# STM32H7B3xxQ register map
File version: 1.0
Registers are 32-bit, read-write, reset 0x0 unless marked. A register's access mark holds for its fields unless they carry their own. Offsets are from the block's base; [hi:lo] are bit positions; {n}, {i} and the like mark numbered series.

## TAMP — Tamper and backup registers
Base 0x58004400
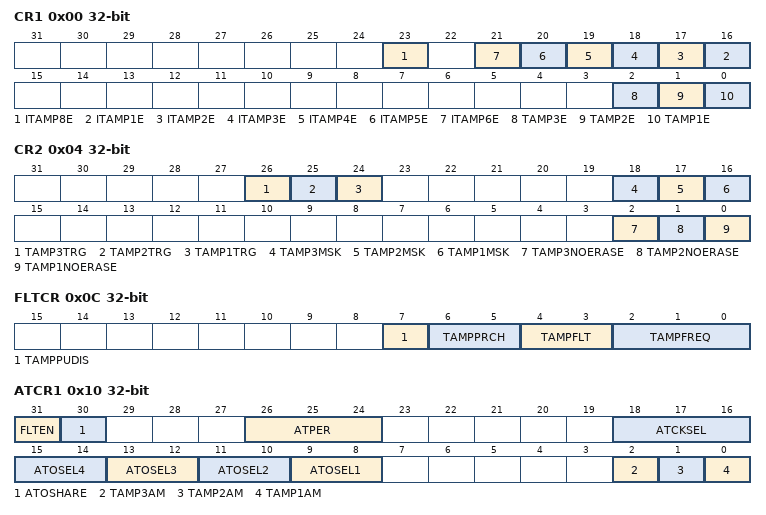
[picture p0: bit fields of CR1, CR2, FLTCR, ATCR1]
0x00 CR1 — TAMP configuration register 1
  [23] ITAMP8E, [n+15] ITAMP{n}E (n=1..6), [2] TAMP3E, [1] TAMP2E, [0] TAMP1E
0x04 CR2 — TAMP configuration register 2
  [26] TAMP3TRG, [25] TAMP2TRG, [24] TAMP1TRG, [18] TAMP3MSK, [17] TAMP2MSK, [16] TAMP1MSK, [2] TAMP3NOERASE, [1] TAMP2NOERASE, [0] TAMP1NOERASE
0x0C FLTCR — TAMP filter control register
  [7] TAMPPUDIS
  [6:5] TAMPPRCH
    0=DURATION_1RTCCLK (Tamper pins are pre-charged before sampling during 1 RTCCLK cycle); 1=DURATION_2RTCCLK (Tamper pins are pre-charged before sampling during 2 RTCCLK cycles); 2=DURATION_4RTCCLK (Tamper pins are pre-charged before sampling during 4 RTCCLK cycles); 3=DURATION_8RTCCLK (Tamper pins are pre-charged before sampling during 8 RTCCLK cycles)
  [4:3] TAMPFLT
    0=DISABLE (Tamper filter is disabled); 1=FILTER_2SAMPLE (Tamper is activated after 2 consecutive samples at the active level); 2=FILTER_4SAMPLE (Tamper is activated after 4 consecutive samples at the active level); 3=FILTER_8SAMPLE (Tamper is activated after 8 consecutive samples at the active level.)
  [2:0] TAMPFREQ
    0=SAMPLFREQDIV_32768 (Each of the tamper inputs are sampled with a frequency = RTCCLK / 32768); 1=SAMPLFREQDIV_16384 (Each of the tamper inputs are sampled with a frequency = RTCCLK / 16384); 2=SAMPLFREQDIV_8192 (Each of the tamper inputs are sampled with a frequency = RTCCLK / 8192); 3=SAMPLFREQDIV_4096 (Each of the tamper inputs are sampled with a frequency = RTCCLK / 4096); 4=SAMPLFREQDIV_2048 (Each of the tamper inputs are sampled with a frequency = RTCCLK / 2048); 5=SAMPLFREQDIV_1024 (Each of the tamper inputs are sampled with a frequency = RTCCLK / 1024); 6=SAMPLFREQDIV_512 (Each of the tamper inputs are sampled with a frequency = RTCCLK / 512); 7=SAMPLFREQDIV_256 (Each of the tamper inputs are sampled with a frequency = RTCCLK / 256)
0x10 ATCR1 — TAMP active tamper control register
  [31] FLTEN, [30] ATOSHARE, [26:24] ATPER, [18:16] ATCKSEL, [2n+7:2n+6] ATOSEL{n} (n=1..4), [2] TAMP3AM, [1] TAMP2AM, [0] TAMP1AM
0x14 ATSEEDR — TAMP active tamper seed register
  [31:0] SEED
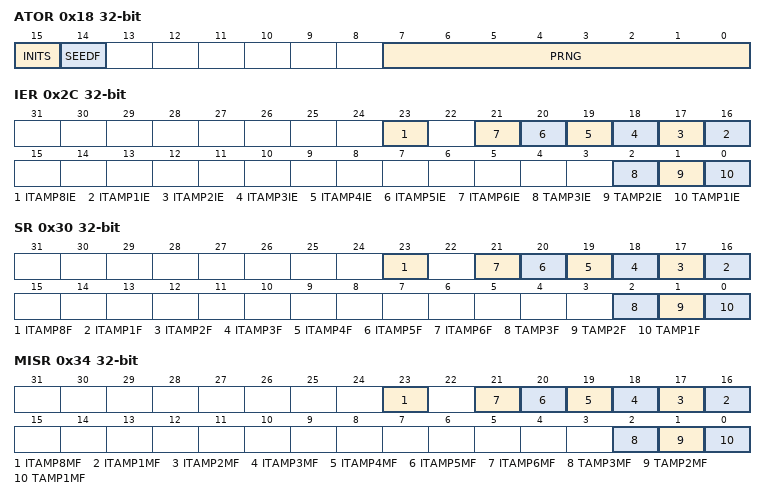
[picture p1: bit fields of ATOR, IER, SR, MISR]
0x18 ATOR — TAMP active tamper output register
  [15] INITS, [14] SEEDF, [7:0] PRNG
0x2C IER — TAMP interrupt enable register
  [23] ITAMP8IE, [n+15] ITAMP{n}IE (n=1..6), [2] TAMP3IE, [1] TAMP2IE, [0] TAMP1IE
0x30 SR — TAMP status register
  [23] ITAMP8F, [n+15] ITAMP{n}F (n=1..6), [2] TAMP3F, [1] TAMP2F, [0] TAMP1F
0x34 MISR — TAMP masked interrupt status register
  [23] ITAMP8MF, [n+15] ITAMP{n}MF (n=1..6), [2] TAMP3MF, [1] TAMP2MF, [0] TAMP1MF
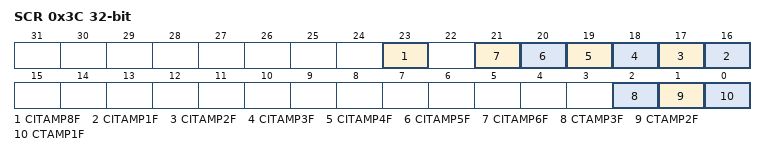
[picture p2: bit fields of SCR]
0x3C SCR — TAMP status clear register
  [23] CITAMP8F, [n+15] CITAMP{n}F (n=1..6), [2] CTAMP3F, [1] CTAMP2F, [0] CTAMP1F
0x40 COUNTR — TAMP monotonic counter register
  [31:16] COUNTR
0x50 CFGR — TAMP configuration register
{0x100+4i} BKP{i}R (i=0..31) — TAMP backup register {i}

## IWDG1 — Independent WATCHDOG
Base 0x58004800
0x00 KR — IWDG Key register
  [15:0] KEY — Key value (write only, read 0000h)
0x04 PR — IWDG Prescaler register
  [2:0] PR — PR[2:0] (Prescaler divider)
0x08 RLR — IWDG Reload register
  [11:0] RL — Watchdog counter reload value
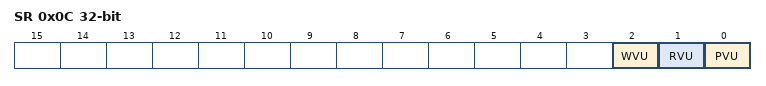
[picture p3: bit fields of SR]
0x0C SR — IWDG Status register
  [2] WVU — Watchdog counter window value update
  [1] RVU — Watchdog counter reload value update
  [0] PVU — Watchdog prescaler value update
0x10 WINR — IWDG Window register
  [11:0] WIN — Watchdog counter window value

## DTS
Base 0x58006800
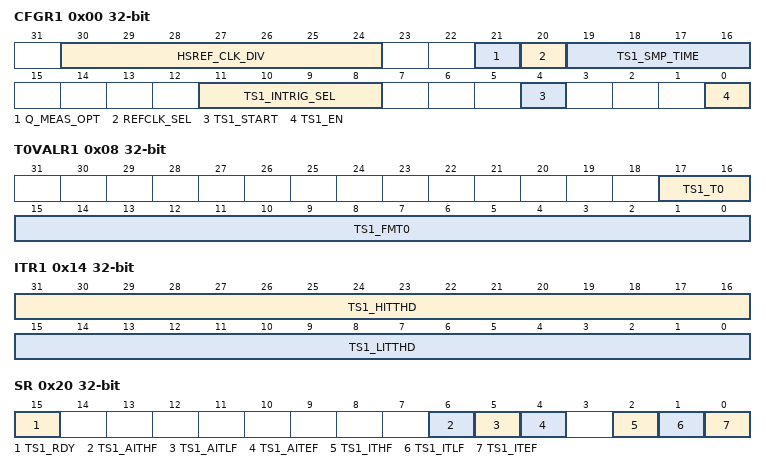
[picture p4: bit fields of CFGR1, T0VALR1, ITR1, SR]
0x00 CFGR1 — DTS configuration register
  [30:24] HSREF_CLK_DIV — High Speed Clock Divider Ratio [6:0]
  [21] Q_MEAS_OPT — Quick measure option bit
  [20] REFCLK_SEL — Reference Clock Selection
  [19:16] TS1_SMP_TIME — Sample time [3:0] for DTS
  [11:8] TS1_INTRIG_SEL — Input triggers selection bits [3:0] for DTS
  [4] TS1_START — Proceed to a frequency measurement on DTS
  [0] TS1_EN — DTS Enable
0x08 T0VALR1 — DTS T0 Value register
  [17:16] TS1_T0 — Engineering value of the DTSerature T0 for DTS
  [15:0] TS1_FMT0 — Engineering value of the measured frequency at T0 for DTS
0x10 RAMPVALR — DTS Ramp value register
  [15:0] TS1_RAMP_COEFF — Engineering value of the ramp coefficient for DTS
0x14 ITR1 — DTS Interrupt threshold register
  [31:16] TS1_HITTHD — High interrupt threshold[15:0] for DTS
  [15:0] TS1_LITTHD — Low interrupt threshold[15:0] for DTS
0x1C DR — DTS data register
  [15:0] TS1_MFREQ — Measured Frequency[15:0] for DTS
0x20 SR — DTS status register
  [15] TS1_RDY — DTS ready flag
  [6] TS1_AITHF — Asynchronous interrupt flag for high threshold for DTS
  [5] TS1_AITLF — Asynchronous interrupt flag for low threshold for DTS
  [4] TS1_AITEF — Asynchronous interrupt flag for end of measure for DTS
  [2] TS1_ITHF — Interrupt flag for high threshold for DTS
  [1] TS1_ITLF — Interrupt flag for low threshold for DTS
  [0] TS1_ITEF — Interrupt flag for end of measure for DTS
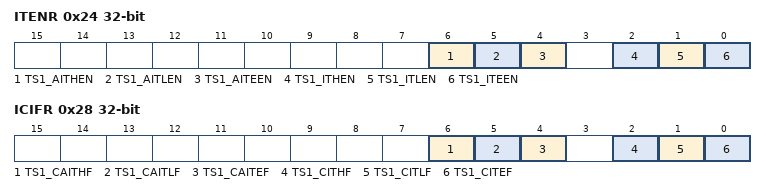
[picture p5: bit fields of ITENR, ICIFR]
0x24 ITENR — DTS Interrupt enable register
  [6] TS1_AITHEN — Enable asynchronous interrupt flag for high threshold for DTS
  [5] TS1_AITLEN — Enable Asynchronous interrupt flag for low threshold for DTS
  [4] TS1_AITEEN — Enable asynchronous interrupt flag for end of measure for DTS
  [2] TS1_ITHEN — Enable interrupt flag for high threshold for DTS
  [1] TS1_ITLEN — Enable interrupt flag for low threshold for DTS
  [0] TS1_ITEEN — Enable interrupt flag for end of measure for DTS
0x28 ICIFR — DTS Clear Interrupt flag register
  [6] TS1_CAITHF — Clear the asynchronous IT flag for high threshold on DTS
  [5] TS1_CAITLF — Clear the asynchronous IT flag for low threshold for DTS
  [4] TS1_CAITEF — Clear the asynchronous IT flag for End Of Measure for DTS
  [2] TS1_CITHF — Clear the IT flag for high threshold on DTS
  [1] TS1_CITLF — Clear the IT flag for low threshold for DTS
  [0] TS1_CITEF — Clear the IT flag for End Of Measure for DTS
0x2C OR — DTS option register 1

## GPIOA — General Purpose I/O
Base 0x58020000
Same registers: GPIOB 0x58020400, GPIOC 0x58020800, GPIOD 0x58020C00, GPIOE 0x58021000, GPIOF 0x58021400, GPIOG 0x58021800, GPIOH 0x58021C00, GPIOI 0x58022000, GPIOJ 0x58022400, GPIOK 0x58022800
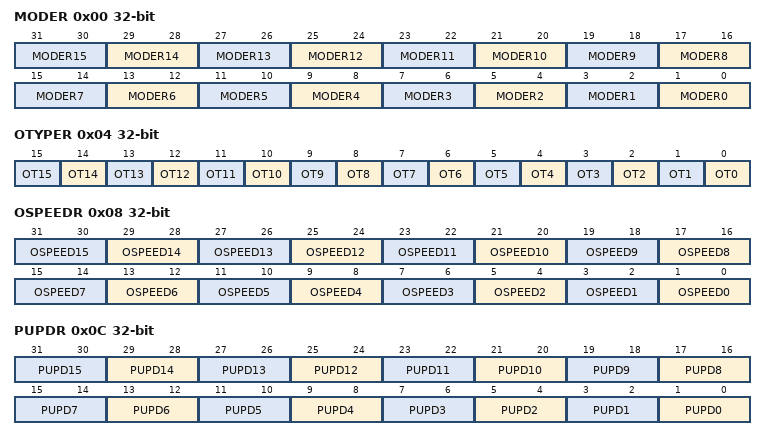
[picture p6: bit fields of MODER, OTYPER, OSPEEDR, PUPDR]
0x00 MODER — GPIO port mode register
  [2n+1:2n] MODER{n} (n=0..15)
0x04 OTYPER — GPIO port output type register
  [n] OT{n} (n=0..15)
0x08 OSPEEDR — GPIO port output speed register
  [2n+1:2n] OSPEED{n} (n=0..15)
0x0C PUPDR — GPIO port pull-up/pull-down register
  [2n+1:2n] PUPD{n} (n=0..15)
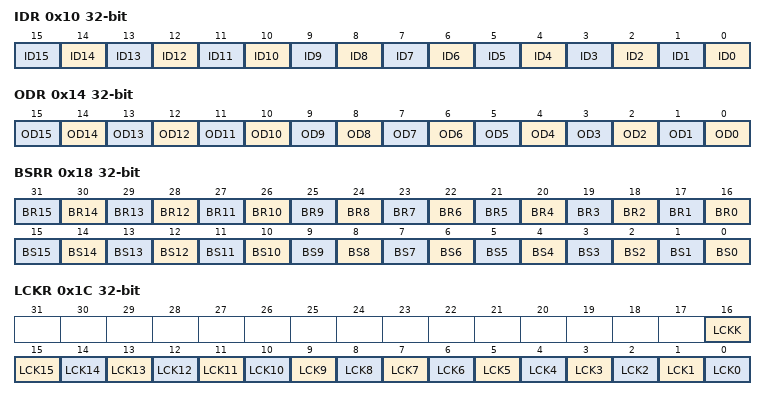
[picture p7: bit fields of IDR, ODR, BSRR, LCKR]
0x10 IDR — GPIO port input data register
  [n] ID{n} (n=0..15)
0x14 ODR — GPIO port output data register
  [n] OD{n} (n=0..15)
0x18 BSRR — GPIO port bit set/reset
  [n+16] BR{n} (n=0..15), [n] BS{n} (n=0..15)
0x1C LCKR — GPIO port configuration lock register
  [16] LCKK, [n] LCK{n} (n=0..15)
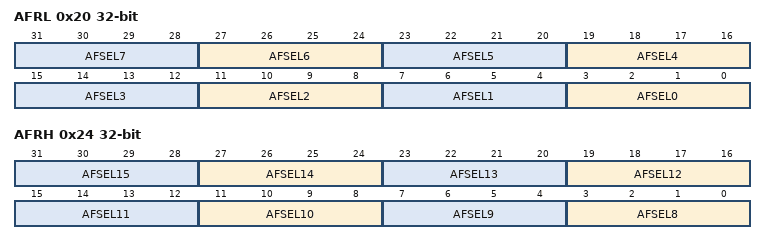
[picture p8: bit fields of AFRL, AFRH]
0x20 AFRL — GPIO alternate function registers
  [4n+3:4n] AFSEL{n} (n=0..7)
0x24 AFRH — GPIO alternate function registers
  [4n-29:4n-32] AFSEL{n} (n=8..15)

## DBGMCU — Debug MCU
Base 0x5C001000
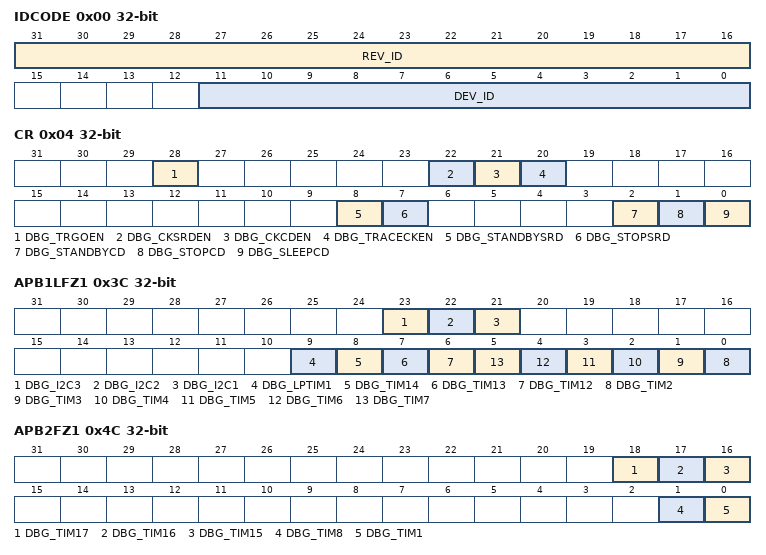
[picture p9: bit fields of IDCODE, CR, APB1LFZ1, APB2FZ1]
0x00 IDCODE — MCU device ID code
  [31:16] REV_ID, [11:0] DEV_ID
0x04 CR — Debug MCU configuration register
  [28] DBG_TRGOEN
    0=INPUT_DIRECTION; 1=OUTPUT_DIRECTION
  [22] DBG_CKSRDEN
  [21] DBG_CKCDEN
  [20] DBG_TRACECKEN
  [8] DBG_STANDBYSRD
  [7] DBG_STOPSRD
  [2] DBG_STANDBYCD
  [1] DBG_STOPCD
  [0] DBG_SLEEPCD
0x34 APB3FZ1 — Debug MCU APB3FZ1 freeze register
  [6] DBG_WWDG1
0x3C APB1LFZ1 — Debug MCU APB1LFZ1 freeze register
  [23] DBG_I2C3, [22] DBG_I2C2, [21] DBG_I2C1, [9] DBG_LPTIM1, [8] DBG_TIM14, [7] DBG_TIM13, [6] DBG_TIM12, [n-2] DBG_TIM{n} (n=2..7)
0x44 APB1HFZ1 — Debug MCU APB1LFZ1 freeze register
0x4C APB2FZ1 — Debug MCU APB2FZ1 freeze register
  [18] DBG_TIM17, [17] DBG_TIM16, [16] DBG_TIM15, [1] DBG_TIM8, [0] DBG_TIM1
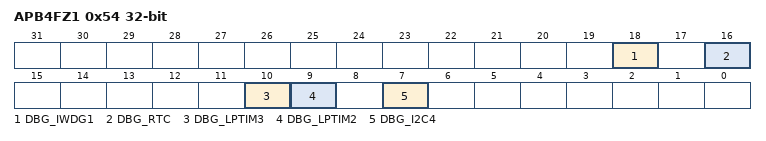
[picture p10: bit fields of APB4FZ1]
0x54 APB4FZ1 — Debug MCU APB4FZ1 freeze register
  [18] DBG_IWDG1, [16] DBG_RTC, [10] DBG_LPTIM3, [9] DBG_LPTIM2, [7] DBG_I2C4
